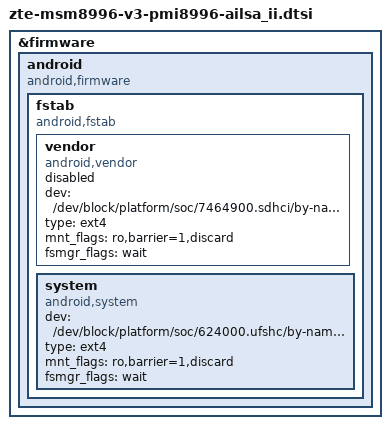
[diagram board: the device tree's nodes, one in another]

#include "touch-key-backlight-ailsa_ii.dtsi"
#include "zte-camera-sensor-mtp.dtsi" //yichangming 400001

&firmware {
	android {
		compatible = "android,firmware";
		fstab {
			compatible = "android,fstab";
			vendor {
				compatible = "android,vendor";
				dev = "/dev/block/platform/soc/7464900.sdhci/by-name/vendor";
				type = "ext4";
				mnt_flags = "ro,barrier=1,discard";
				fsmgr_flags = "wait";
				status = "disabled";
			 };
			 system {
				compatible = "android,system";
				dev = "/dev/block/platform/soc/624000.ufshc/by-name/system";
				type = "ext4";
				mnt_flags = "ro,barrier=1,discard";
				fsmgr_flags = "wait";
				status = "ok";
			};

		};
	};
};
